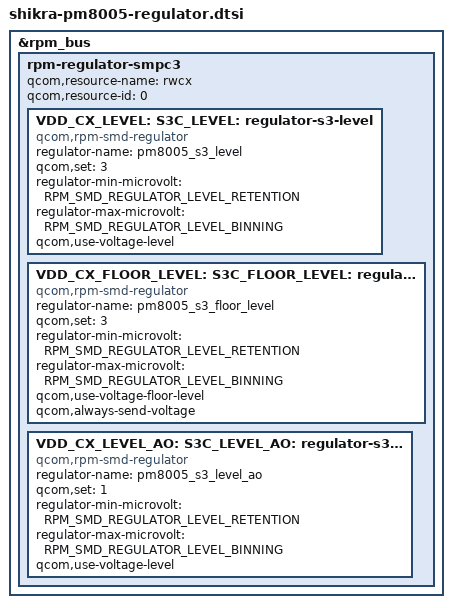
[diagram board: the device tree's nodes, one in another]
// SPDX-License-Identifier: BSD-3-Clause
/*
 * Copyright (c) Qualcomm Technologies, Inc. and/or its subsidiaries.
 */

#include <dt-bindings/regulator/qcom,rpm-smd-regulator.h>
#include "pm8005-rpm-regulator.dtsi"

&rpm_bus {
	/* PM8005 S3C - VDD_CX supply */
	rpm-regulator-smpc3 {
		status = "okay";
		qcom,resource-name = "rwcx";
		qcom,resource-id = <0>;

		VDD_CX_LEVEL:
		S3C_LEVEL: pm8005_s3_level: regulator-s3-level {
			compatible = "qcom,rpm-smd-regulator";
			regulator-name = "pm8005_s3_level";
			qcom,set = <3>;
			regulator-min-microvolt =
					<RPM_SMD_REGULATOR_LEVEL_RETENTION>;
			regulator-max-microvolt =
					<RPM_SMD_REGULATOR_LEVEL_BINNING>;
			qcom,use-voltage-level;
		};

		VDD_CX_FLOOR_LEVEL:
		S3C_FLOOR_LEVEL:
		pm8005_s3_floor_level: regulator-s3-floor-level {
			compatible = "qcom,rpm-smd-regulator";
			regulator-name = "pm8005_s3_floor_level";
			qcom,set = <3>;
			regulator-min-microvolt =
					<RPM_SMD_REGULATOR_LEVEL_RETENTION>;
			regulator-max-microvolt =
					<RPM_SMD_REGULATOR_LEVEL_BINNING>;
			qcom,use-voltage-floor-level;
			qcom,always-send-voltage;
		};

		VDD_CX_LEVEL_AO:
		S3C_LEVEL_AO: pm8005_s3_level_ao: regulator-s3-level-ao {
			compatible = "qcom,rpm-smd-regulator";
			regulator-name = "pm8005_s3_level_ao";
			qcom,set = <1>;
			regulator-min-microvolt =
					<RPM_SMD_REGULATOR_LEVEL_RETENTION>;
			regulator-max-microvolt =
					<RPM_SMD_REGULATOR_LEVEL_BINNING>;
			qcom,use-voltage-level;
		};
	};
};
